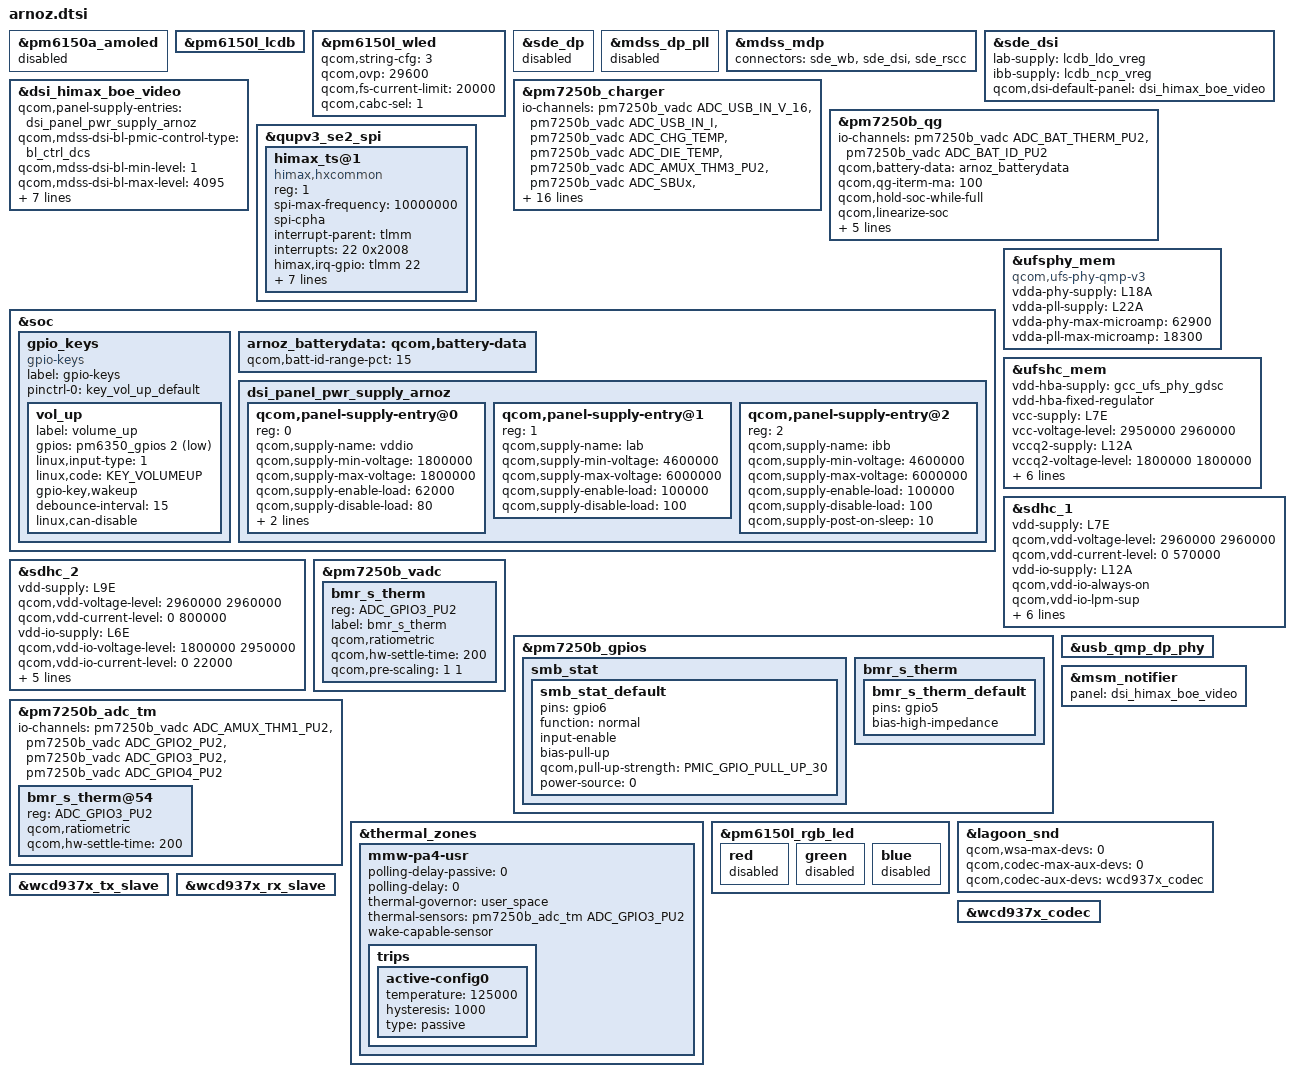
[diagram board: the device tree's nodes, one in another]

#include "arnoz-pinctrl.dtsi"
#include "lagoon-audio-overlay.dtsi"
#include "lagoon-thermal-overlay.dtsi"
#include "lagoon-sde-display.dtsi"
#include "dsi-panel-himax-boe-video.dtsi"
#include <dt-bindings/pinctrl/qcom,pmic-gpio.h>
#include <dt-bindings/iio/qcom,spmi-vadc.h>
#include <dt-bindings/gpio/gpio.h>
#include <dt-bindings/input/linux-event-codes.h>

&pm6150a_amoled {
	status = "disabled";
};

&pm6150l_lcdb {
	status = "ok";
	/delete-property/ qcom,voltage-step-ramp;
};

&pm6150l_wled {
	status = "ok";
	qcom,string-cfg = <3>;
	qcom,ovp = <29600>;
	qcom,fs-current-limit = <20000>;
	qcom,cabc-sel = <1>;
};

&sde_dp {
	status = "disabled";
};

&mdss_dp_pll {
	status = "disabled";
};

&mdss_mdp {
	connectors = <&sde_wb &sde_dsi &sde_rscc>;
};

&sde_dsi {
	/delete-property/ vdd-supply;
	lab-supply = <&lcdb_ldo_vreg>;
	ibb-supply = <&lcdb_ncp_vreg>;
	qcom,dsi-default-panel = <&dsi_himax_boe_video>;
};

&dsi_himax_boe_video {
	qcom,panel-supply-entries = <&dsi_panel_pwr_supply_arnoz>;
	qcom,mdss-dsi-bl-pmic-control-type = "bl_ctrl_dcs";
	qcom,mdss-dsi-bl-min-level = <1>;
	qcom,mdss-dsi-bl-max-level = <4095>;
	qcom,mdss-brightness-max-level = <255>;
	qcom,platform-te-gpio = <&tlmm 23 0>;
	qcom,platform-en-gpio = <&tlmm 49 0>;
	qcom,lcm-enp-gpio = <&tlmm 47 0>;
	qcom,lcm-enn-gpio = <&tlmm 55 0>;
	qcom,platform-bklight-en-gpio = <&tlmm 41 0>;
	qcom,platform-reset-gpio = <&pm6150l_gpios 9 0>;
};

&pm7250b_charger {
	status = "ok";
	io-channels = <&pm7250b_vadc ADC_USB_IN_V_16>,
		      <&pm7250b_vadc ADC_USB_IN_I>,
		      <&pm7250b_vadc ADC_CHG_TEMP>,
		      <&pm7250b_vadc ADC_DIE_TEMP>,
		      <&pm7250b_vadc ADC_AMUX_THM3_PU2>,
		      <&pm7250b_vadc ADC_SBUx>,
		      <&pm7250b_vadc ADC_VPH_PWR>,
		      <&pm7250b_vadc ADC_AMUX_THM1_PU2>;
	io-channel-names = "usb_in_voltage",
			   "usb_in_current",
			   "chg_temp",
			   "die_temp",
			   "conn_temp",
			   "sbux_res",
			   "vph_voltage",
			   "skin_temp";
	qcom,battery-data = <&arnoz_batterydata>;
	qcom,sec-charger-config = <1>;
	qcom,auto-recharge-soc = <98>;
	qcom,step-charging-enable;
	qcom,sw-jeita-enable;
	qcom,charger-temp-max = <800>;
	qcom,smb-temp-max = <800>;
	qcom,suspend-input-on-debug-batt;
	qcom,fcc-stepping-enable;
	qcom,fcc-step-delay-ms = <100>;
	qcom,fcc-step-size-ua = <100000>;
	qcom,smb-internal-pull-kohm = <0>;
	qcom,en-skin-therm-mitigation;
	qcom,hvdcp3-standalone-config;
};

&pm7250b_qg {
	status = "ok";
	io-channels = <&pm7250b_vadc ADC_BAT_THERM_PU2>,
		      <&pm7250b_vadc ADC_BAT_ID_PU2>;
	io-channel-names = "batt-therm",
			   "batt-id";
	qcom,battery-data = <&arnoz_batterydata>;
	qcom,qg-iterm-ma = <100>;
	qcom,hold-soc-while-full;
	qcom,linearize-soc;
	qcom,cl-feedback-on;
	qcom,tcss-enable;
	qcom,fvss-enable;
	qcom,fvss-vbatt-mv = <3300>;
	qcom,bass-enable;
};

/* Touchscreen - Himax HX83102 on qupv3_se2_spi */
&qupv3_se2_spi {
	status = "ok";
	himax_ts@1 {
		compatible = "himax,hxcommon";
		reg = <1>;
		spi-max-frequency = <10000000>;
		spi-cpha;
		interrupt-parent = <&tlmm>;
		interrupts = <22 0x2008>;
		himax,irq-gpio = <&tlmm 22 0x2008>;
		himax,rst-gpio = <&tlmm 21 0x00>;
		himax,panel-coords = <0 1200 0 2000>;
		himax,display-coords = <0 1200 0 2000>;
		report_type = <1>;
		panel = <&dsi_himax_boe_video>;
		pinctrl-names = "pmx_ts_active", "pmx_ts_suspend";
		pinctrl-0 = <&ts_int_active &ts_reset_active>;
		pinctrl-1 = <&ts_int_suspend &ts_reset_suspend>;
	};
};

&soc {
	gpio_keys {
		compatible = "gpio-keys";
		label = "gpio-keys";
		pinctrl-names = "default";
		pinctrl-0 = <&key_vol_up_default>;
		vol_up {
			label = "volume_up";
			gpios = <&pm6350_gpios 2 GPIO_ACTIVE_LOW>;
			linux,input-type = <1>;
			linux,code = <KEY_VOLUMEUP>;
			gpio-key,wakeup;
			debounce-interval = <15>;
			linux,can-disable;
		};
	};

	arnoz_batterydata: qcom,battery-data {
		qcom,batt-id-range-pct = <15>;
		#include "arnoz-batterydata.dtsi"
	};

	dsi_panel_pwr_supply_arnoz: dsi_panel_pwr_supply_arnoz {
		#address-cells = <1>;
		#size-cells = <0>;
		qcom,panel-supply-entry@0 {
			reg = <0>;
			qcom,supply-name = "vddio";
			qcom,supply-min-voltage = <1800000>;
			qcom,supply-max-voltage = <1800000>;
			qcom,supply-enable-load = <62000>;
			qcom,supply-disable-load = <80>;
			qcom,supply-post-on-sleep = <1>;
			qcom,supply-post-off-sleep = <20>;
		};
		qcom,panel-supply-entry@1 {
			reg = <1>;
			qcom,supply-name = "lab";
			qcom,supply-min-voltage = <4600000>;
			qcom,supply-max-voltage = <6000000>;
			qcom,supply-enable-load = <100000>;
			qcom,supply-disable-load = <100>;
		};
		qcom,panel-supply-entry@2 {
			reg = <2>;
			qcom,supply-name = "ibb";
			qcom,supply-min-voltage = <4600000>;
			qcom,supply-max-voltage = <6000000>;
			qcom,supply-enable-load = <100000>;
			qcom,supply-disable-load = <100>;
			qcom,supply-post-on-sleep = <10>;
		};
	};
};

&ufsphy_mem {
	compatible = "qcom,ufs-phy-qmp-v3";
	vdda-phy-supply = <&L18A>;
	vdda-pll-supply = <&L22A>;
	vdda-phy-max-microamp = <62900>;
	vdda-pll-max-microamp = <18300>;
	status = "ok";
};

&ufshc_mem {
	vdd-hba-supply = <&gcc_ufs_phy_gdsc>;
	vdd-hba-fixed-regulator;
	vcc-supply = <&L7E>;
	vcc-voltage-level = <2950000 2960000>;
	vccq2-supply = <&L12A>;
	vccq2-voltage-level = <1800000 1800000>;
	vcc-max-microamp = <800000>;
	vccq2-max-microamp = <800000>;
	qcom,vddp-ref-clk-supply = <&L22A>;
	qcom,vddp-ref-clk-max-microamp = <100>;
	qcom,vddp-ref-clk-min-uV = <1152000>;
	qcom,vddp-ref-clk-max-uV = <1200000>;
	status = "ok";
};

&sdhc_1 {
	vdd-supply = <&L7E>;
	qcom,vdd-voltage-level = <2960000 2960000>;
	qcom,vdd-current-level = <0 570000>;
	vdd-io-supply = <&L12A>;
	qcom,vdd-io-always-on;
	qcom,vdd-io-lpm-sup;
	qcom,vdd-io-voltage-level = <1800000 1800000>;
	qcom,vdd-io-current-level = <0 325000>;
	pinctrl-names = "active", "sleep";
	pinctrl-0 = <&sdc1_clk_on &sdc1_cmd_on &sdc1_data_on &sdc1_rclk_on>;
	pinctrl-1 = <&sdc1_clk_off &sdc1_cmd_off &sdc1_data_off &sdc1_rclk_off>;
	status = "ok";
};

&sdhc_2 {
	vdd-supply = <&L9E>;
	qcom,vdd-voltage-level = <2960000 2960000>;
	qcom,vdd-current-level = <0 800000>;
	vdd-io-supply = <&L6E>;
	qcom,vdd-io-voltage-level = <1800000 2950000>;
	qcom,vdd-io-current-level = <0 22000>;
	pinctrl-names = "active", "sleep";
	pinctrl-0 = <&sdc2_clk_on &sdc2_cmd_on &sdc2_data_on &sdc2_cd_on>;
	pinctrl-1 = <&sdc2_clk_off &sdc2_cmd_off &sdc2_data_off &sdc2_cd_off>;
	cd-gpios = <&tlmm 69 GPIO_ACTIVE_LOW>;
	status = "ok";
};

&pm7250b_vadc {
	bmr_s_therm {
		reg = <ADC_GPIO3_PU2>;
		label = "bmr_s_therm";
		qcom,ratiometric;
		qcom,hw-settle-time = <200>;
		qcom,pre-scaling = <1 1>;
	};
};

&pm7250b_gpios {
	smb_stat {
		smb_stat_default: smb_stat_default {
			pins = "gpio6";
			function = "normal";
			input-enable;
			bias-pull-up;
			qcom,pull-up-strength = <PMIC_GPIO_PULL_UP_30>;
			power-source = <0>;
		};
	};
	bmr_s_therm {
		bmr_s_therm_default: bmr_s_therm_default {
			pins = "gpio5";
			bias-high-impedance;
		};
	};
};

&pm7250b_adc_tm {
	io-channels = <&pm7250b_vadc ADC_AMUX_THM1_PU2>,
			<&pm7250b_vadc ADC_GPIO2_PU2>,
			<&pm7250b_vadc ADC_GPIO3_PU2>,
			<&pm7250b_vadc ADC_GPIO4_PU2>;
	bmr_s_therm@54 {
		reg = <ADC_GPIO3_PU2>;
		qcom,ratiometric;
		qcom,hw-settle-time = <200>;
	};
};

&thermal_zones {
	mmw-pa4-usr {
		polling-delay-passive = <0>;
		polling-delay = <0>;
		thermal-governor = "user_space";
		thermal-sensors = <&pm7250b_adc_tm ADC_GPIO3_PU2>;
		wake-capable-sensor;
		trips {
			active-config0 {
				temperature = <125000>;
				hysteresis = <1000>;
				type = "passive";
			};
		};
	};
};

&usb_qmp_dp_phy {
	/* vdd-supply is handled by lagoon.dtsi */
};

&pm6150l_rgb_led {
	red {
		status = "disabled";
	};
	green {
		status = "disabled";
	};
	blue {
		status = "disabled";
	};
};

&msm_notifier {
	panel = <&dsi_himax_boe_video>;
};

/*
 * Audio: J607F (arnoz) has no WSA speakers, uses WCD937x codec + CS35L41 amps.
 * Override lagoon-audio-overlay.dtsi defaults to prevent machine driver
 * from waiting indefinitely for non-existent WSA883x components.
 */
&lagoon_snd {
	qcom,wsa-max-devs = <0>;
	/delete-property/ qcom,wsa-devs;
	/delete-property/ qcom,wsa-aux-dev-prefix;

	qcom,codec-max-aux-devs = <0>;
	qcom,codec-aux-devs = <&wcd937x_codec>;
};

&wcd937x_tx_slave {
	status = "ok";
};

&wcd937x_rx_slave {
	status = "ok";
};

&wcd937x_codec {
	status = "ok";
};
